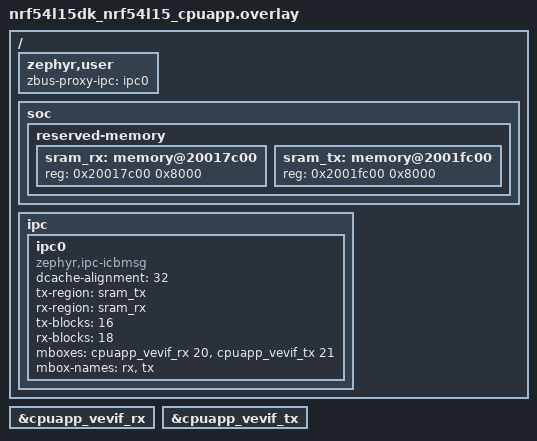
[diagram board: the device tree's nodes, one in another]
/*
 * Copyright (c) 2026 Nordic Semiconductor ASA
 *
 * SPDX-License-Identifier: Apache-2.0
 */

/ {
	zephyr,user {
		zbus-proxy-ipc = <&ipc0>;
	};

	soc {
		reserved-memory {
			#address-cells = <1>;
			#size-cells = <1>;

			sram_rx: memory@20017c00 {
				reg = <0x20017c00 0x8000>;
			};

			sram_tx: memory@2001fc00 {
				reg = <0x2001fc00 0x8000>;
			};
		};
	};

	ipc {
		ipc0: ipc0 {
			compatible = "zephyr,ipc-icbmsg";
			dcache-alignment = <32>;
			tx-region = <&sram_tx>;
			rx-region = <&sram_rx>;
			tx-blocks = <16>;
			rx-blocks = <18>;
			mboxes = <&cpuapp_vevif_rx 20>, <&cpuapp_vevif_tx 21>;
			mbox-names = "rx", "tx";
			status = "okay";
		};
	};
};

&cpuapp_vevif_rx {
	status = "okay";
};

&cpuapp_vevif_tx {
	status = "okay";
};
